# FM33FG0XXA register map
File version: 1.0
CPU: SC000 r1p0, little endian, MPU, no FPU, 3 interrupt priority bits
Registers are 32-bit, read-only, reset 0x0 unless marked. A register's access mark holds for its fields unless they carry their own. Offsets are from the block's base; [hi:lo] are bit positions; {n}, {i} and the like mark numbered series.

## RMU — RMU module information
Base 0x40002800
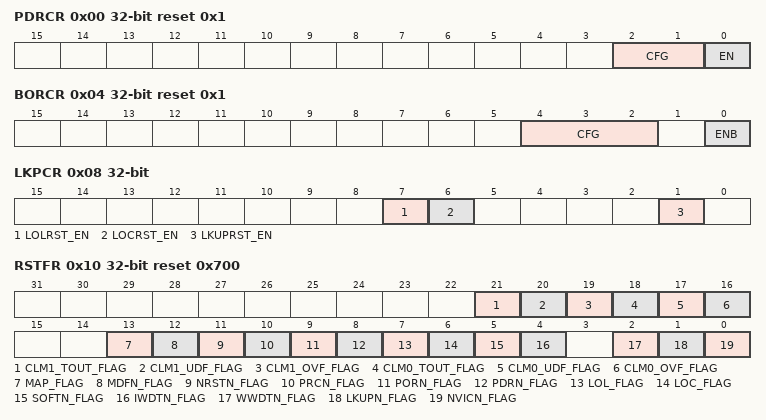
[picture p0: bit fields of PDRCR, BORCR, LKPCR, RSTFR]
0x00 PDRCR rw reset 0x1 — PDR Control Register
  [2:1] CFG — CFG field description
  [0] EN — EN field description
0x04 BORCR rw reset 0x1 — BOR Control Register
  [4:2] CFG — CFG field description
  [0] ENB — ENB field description
0x08 LKPCR rw — Reset Config Register
  [7] LOLRST_EN — LOLRST_EN field description
  [6] LOCRST_EN — LOCRST_EN field description
  [1] LKUPRST_EN — LKUPRST_EN field description
0x0C SOFTRST wo — Software Reset Register
  [31:0] SOFTRST — SOFTRST field description
0x10 RSTFR rw reset 0x700 — Reset Flag Register
  [21] CLM1_TOUT_FLAG — CLM1_TOUT_FLAG field description
  [20] CLM1_UDF_FLAG — CLM1_UDF_FLAG field description
  [19] CLM1_OVF_FLAG — CLM1_OVF_FLAG field description
  [18] CLM0_TOUT_FLAG — CLM0_TOUT_FLAG field description
  [17] CLM0_UDF_FLAG — CLM0_UDF_FLAG field description
  [16] CLM0_OVF_FLAG — CLM0_OVF_FLAG field description
  [13] MAP_FLAG — MAP_FLAG field description
  [12] MDFN_FLAG — MDFN_FLAG field description
  [11] NRSTN_FLAG — NRSTN_FLAG field description
  [10] PRCN_FLAG — PRCN_FLAG field description
  [9] PORN_FLAG — PORN_FLAG field description
  [8] PDRN_FLAG — PDRN_FLAG field description
  [7] LOL_FLAG — LOL_FLAG field description
  [6] LOC_FLAG — LOC_FLAG field description
  [5] SOFTN_FLAG — SOFTN_FLAG field description
  [4] IWDTN_FLAG — IWDTN_FLAG field description
  [2] WWDTN_FLAG — WWDTN_FLAG field description
  [1] LKUPN_FLAG — LKUPN_FLAG field description
  [0] NVICN_FLAG — NVICN_FLAG field description
0x14 PRSTEN wo — Peripheral Reset Enable Register
  [31:0] PERHRSTEN — PERHRSTEN field description
0x18 AHBRSTCR rw — Peripheral Reset Enable Register
  [0] DMARST — DMARST field description
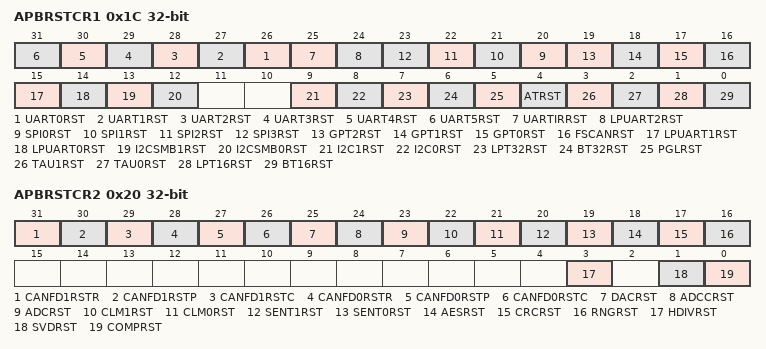
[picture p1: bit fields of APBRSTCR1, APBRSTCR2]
0x1C APBRSTCR1 rw — APB Peripherals Reset Register1
  [n+26] UART{n}RST (n=0..5) — UART{n}RST field description
  [25] UARTIRRST — UARTIRRST field description
  [24] LPUART2RST — LPUART2RST field description
  [n+20] SPI{n}RST (n=0..3) — SPI{n}RST field description
  [19] GPT2RST — GPT2RST field description
  [18] GPT1RST — GPT1RST field description
  [17] GPT0RST — GPT0RST field description
  [16] FSCANRST — FSCANRST field description
  [15] LPUART1RST — LPUART1RST field description
  [14] LPUART0RST — LPUART0RST field description
  [13] I2CSMB1RST — I2CSMB1RST field description
  [12] I2CSMB0RST — I2CSMB0RST field description
  [9] I2C1RST — I2C1RST field description
  [8] I2C0RST — I2C0RST field description
  [7] LPT32RST — LPT32RST field description
  [6] BT32RST — BT32RST field description
  [5] PGLRST — PGLRST field description
  [4] ATRST — ATRST field description
  [3] TAU1RST — TAU1RST field description
  [2] TAU0RST — TAU0RST field description
  [1] LPT16RST — LPT16RST field description
  [0] BT16RST — BT16RST field description
0x20 APBRSTCR2 rw — APB Peripherals Reset Register1
  [31] CANFD1RSTR — CANFD1RSTR field description
  [30] CANFD1RSTP — CANFD1RSTP field description
  [29] CANFD1RSTC — CANFD1RSTC field description
  [28] CANFD0RSTR — CANFD0RSTR field description
  [27] CANFD0RSTP — CANFD0RSTP field description
  [26] CANFD0RSTC — CANFD0RSTC field description
  [25] DACRST — DACRST field description
  [24] ADCCRST — ADCCRST field description
  [23] ADCRST — ADCRST field description
  [22] CLM1RST — CLM1RST field description
  [21] CLM0RST — CLM0RST field description
  [20] SENT1RST — SENT1RST field description
  [19] SENT0RST — SENT0RST field description
  [18] AESRST — AESRST field description
  [17] CRCRST — CRCRST field description
  [16] RNGRST — RNGRST field description
  [3] HDIVRST — HDIVRST field description
  [1] SVDRST — SVDRST field description
  [0] COMPRST — COMPRST field description
